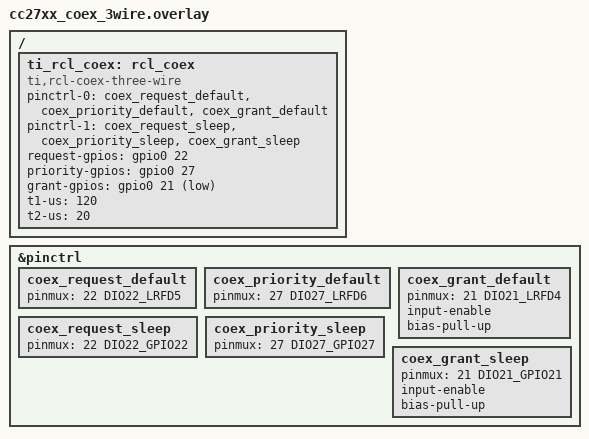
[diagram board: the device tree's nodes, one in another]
/*
 * Copyright (c) 2026 Texas Instruments Incorporated
 *
 * SPDX-License-Identifier: Apache-2.0
 */

#include <zephyr/dt-bindings/pinctrl/cc27xx-pinctrl.h>
#include <zephyr/dt-bindings/gpio/gpio.h>

&pinctrl {
	coex_request_default: coex_request_default {
		pinmux = <22 DIO22_LRFD5>;	/* REQUEST - output using LRFD5 */
	};

	coex_priority_default: coex_priority_default {
		pinmux = <27 DIO27_LRFD6>;	/* PRIORITY - output using LRFD6 */
	};

	coex_grant_default: coex_grant_default {
		pinmux = <21 DIO21_LRFD4>;	/* GRANT - input using LRFD4 */
		input-enable;
		bias-pull-up;
	};

	coex_request_sleep: coex_request_sleep {
		pinmux = <22 DIO22_GPIO22>;
	};

	coex_priority_sleep: coex_priority_sleep {
		pinmux = <27 DIO27_GPIO27>;
	};

	coex_grant_sleep: coex_grant_sleep {
		pinmux = <21 DIO21_GPIO21>;
		input-enable;
		bias-pull-up;
	};
};

/ {
	ti_rcl_coex: rcl_coex {
		compatible = "ti,rcl-coex-three-wire";
		status = "okay";

		pinctrl-0 = <&coex_request_default &coex_priority_default &coex_grant_default>;
		pinctrl-1 = <&coex_request_sleep &coex_priority_sleep &coex_grant_sleep>;
		pinctrl-names = "default", "sleep";

		request-gpios = <&gpio0 22 GPIO_ACTIVE_HIGH>;
		priority-gpios = <&gpio0 27 GPIO_ACTIVE_HIGH>;
		grant-gpios = <&gpio0 21 GPIO_ACTIVE_LOW>;

		t1-us = <120>;  /* Time between REQUEST and RF activity (90-150 µs) */
		t2-us = <20>;   /* Priority indication time (15-20 µs) */
	};
};
